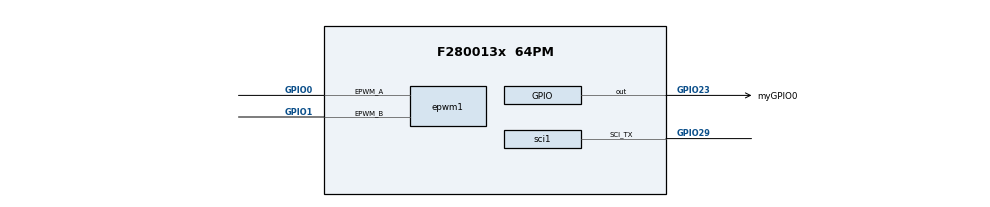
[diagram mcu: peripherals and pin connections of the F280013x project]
/**
 * @cliArgs --device "F280013x" --part "F280013x_64PM" --package "64PM" --context "system" --product "C2000WARE@6.00.00.00"
 * @versions {"tool":"1.24.0+4110"}
 */

/**
 * Import the modules used in this configuration.
 */
const adc     = scripting.addModule("/driverlib/adc.js", {}, false);
const adc1    = adc.addInstance();
const analog  = scripting.addModule("/driverlib/analog.js", {}, false);
const analog1 = analog.addInstance();
const epwm    = scripting.addModule("/driverlib/epwm.js", {}, false);
const epwm1   = epwm.addInstance();
const gpio    = scripting.addModule("/driverlib/gpio.js", {}, false);
const gpio1   = gpio.addInstance();
const gpio2   = gpio.addInstance();
const gpio3   = gpio.addInstance();
const sci     = scripting.addModule("/driverlib/sci.js", {}, false);
const sci1    = sci.addInstance();
const sci2    = sci.addInstance();

/**
 * Write custom configuration values to the imported modules.
 */
adc1.$name                   = "myADC0";
adc1.adcClockPrescaler       = "ADC_CLK_DIV_3_0";
adc1.enabledSOCs             = ["ADC_SOC_NUMBER0"];
adc1.soc0SampleWindow        = 9;
adc1.soc0Trigger             = "ADC_TRIGGER_EPWM1_SOCA";
adc1.registerInterrupts      = ["1"];
adc1.interruptPulseMode      = "ADC_PULSE_END_OF_CONV";
adc1.enabledInts             = ["ADC_INT_NUMBER1"];
adc1.enableInterrupt1        = true;
adc1.adcInt1.enableInterrupt = true;

analog1.$name            = "myANALOGPinMux0";
adc1.analog              = analog1;
analog1.useCase          = "CUSTOM";
analog1.useInterfacePins = ["A0/C15/CMP1_DACL"];

epwm1.$name                                                      = "myEPWM0";
epwm1.epwmTimebase_period                                        = 2999;
epwm1.epwmTimebase_counterMode                                   = "EPWM_COUNTER_MODE_UP_DOWN";
epwm1.epwmCounterCompare_cmpA                                    = 1500;
epwm1.epwmActionQualifier_EPWM_AQ_OUTPUT_A_ON_TIMEBASE_UP_CMPA   = "EPWM_AQ_OUTPUT_HIGH";
epwm1.epwmActionQualifier_EPWM_AQ_OUTPUT_A_ON_TIMEBASE_DOWN_CMPA = "EPWM_AQ_OUTPUT_LOW";
epwm1.epwmActionQualifier_EPWM_AQ_OUTPUT_B_ON_TIMEBASE_UP_CMPA   = "EPWM_AQ_OUTPUT_LOW";
epwm1.epwmActionQualifier_EPWM_AQ_OUTPUT_B_ON_TIMEBASE_DOWN_CMPA = "EPWM_AQ_OUTPUT_HIGH";
epwm1.epwmDeadband_delayRED                                      = 60;
epwm1.epwmDeadband_delayFED                                      = 60;
epwm1.epwmEventTrigger_EPWM_SOC_A_triggerEnable                  = true;
epwm1.epwmEventTrigger_EPWM_SOC_A_triggerEventPrescalar          = "1";
epwm1.epwmDeadband_enableRED                                     = true;
epwm1.epwmDeadband_enableFED                                     = true;
epwm1.epwmDeadband_polarityFED                                   = "EPWM_DB_POLARITY_ACTIVE_LOW";
epwm1.epwmEventTrigger_EPWM_SOC_A_triggerSource                  = "EPWM_SOC_TBCTR_U_CMPA";
epwm1.epwm.$assign                                               = "EPWM1";
epwm1.epwm.epwm_aPin.$assign                                     = "GPIO0";
epwm1.epwm.epwm_bPin.$assign                                     = "GPIO1";

gpio1.$name           = "myGPIO0";
gpio1.direction       = "GPIO_DIR_MODE_OUT";
gpio1.gpioPin.$assign = "GPIO23";

gpio2.$name = "myBootPin1";

gpio3.$name = "myBootPin2";

sci1.$name                 = "mySCI0";
sci1.baudRates             = 115600;
sci1.sci.sci_txPin.$assign = "GPIO29";
sci1.rxQual.$name          = "myGPIOQUAL0";
sci1.txQual.$name          = "myGPIOQUAL1";

sci2.$name        = "mySCI1";
sci2.rxQual.$name = "myGPIOQUAL2";
sci2.txQual.$name = "myGPIOQUAL3";

/**
 * Pinmux solution for unlocked pins/peripherals. This ensures that minor changes to the automatic solver in a future
 * version of the tool will not impact the pinmux you originally saw.  These lines can be completely deleted in order to
 * re-solve from scratch.
 */
analog1.analog.$suggestSolution                        = "ANALOG";
analog1.analog["a0/c15/cmp1_daclPin"].$suggestSolution = "A0/C15/CMP1_DACL";
gpio2.gpioPin.$suggestSolution                         = "A6, GPIO228";
gpio3.gpioPin.$suggestSolution                         = "C6, GPIO226";
sci1.sci.$suggestSolution                              = "SCIA";
sci1.sci.sci_rxPin.$suggestSolution                    = "A16/C16, GPIO28";
sci2.sci.$suggestSolution                              = "SCIB";
sci2.sci.sci_rxPin.$suggestSolution                    = "A19/C19, GPIO13";
sci2.sci.sci_txPin.$suggestSolution                    = "A20/C20, GPIO12";
